# DA14581 register map
Vendor: Dialog; Series: DA1458x; File version: 1.2
Ultra-Low power Bleutooth 4.2 SoC with Optimized Boot Time from Dialog Semiconductor
CPU: CM0 r1p0, little endian, MPU, FPU, 3 interrupt priority bits
Registers are 16-bit, read-write, reset 0x0 unless marked. A register's access mark holds for its fields unless they carry their own. Offsets are from the block's base; lines under a group give offsets from that group; [hi:lo] are bit positions; {n}, {i} and the like mark numbered series; 'fields as' and 'values as' point back to an identical list; <NAME> marks a mode.

## Memory map
0x40000000 ble580_gr01 size 0x208 — ble580_gr01 registers
0x40008000 otpc580_gr01 size 0x20 — otpc580_gr01 registers
0x50000000 crg580_nl01 size 0x2C — crg580_nl01 registers
0x50000080 crg580_dcdc_nl01 size 0x6 — crg580_dcdc_nl01 registers
0x50000100 wkup580_nl01 size 0x1A — wkup580_nl01 registers
0x50000200 quadec580_gr01 size 0xC — quadec580_gr01 registers
0x50001000 UART1 size 0xFE — UART1 registers
0x50001100 UART2 size 0xFE — UART2 registers
0x50001200 spi443_nl00 size 0xA — spi443_nl00 registers
0x50001300 i2c580_nl00 size 0xA2 — i2c580_nl00 registers
0x50001400 kbrd580_nl01 size 0x18 — kbrd580_nl01 registers
0x50001500 adc580_bif_nl01 size 0x10 — adc580_bif_nl01 registers
0x50001600 anamisc580_nl01 size 0x8 — anamisc580_nl01 registers
0x50003000 gpio580_ports_nl01 size 0x96 — gpio580_ports_nl01 registers
0x50003100 riscutil580_wdog_nl00 size 0x4 — riscutil580_wdog_nl00 registers
0x50003200 CHIP_VERSION size 0x5 — CHIP_VERSION registers
0x50003300 riscutil580_gpreg_nl01 size 0xA — riscutil580_gpreg_nl01 registers
0x50003400 tmr580_nl01 size 0x12 — tmr580_nl01 registers
0xE000E010 SysTick size 0x11 — Cortex M0 SysTick registers
0xE000E100 NVIC size 0x321 — Cortex M0 NVIC registers
0xE000ED00 SCB size 0x29 — Cortex M0 SCB registers

## Interrupts
0 BLE_WAKEUP_LP (wkup580_nl01) — Wake-up from Low Power (Extended Sleep) interrupt from BLE
1 BLE_GEN (wkup580_nl01) — BLE Interrupt from various BLE sources.
2 UART (wkup580_nl01) — UART interrupt
3 UART2 (wkup580_nl01) — UART2 interrupt
4 I2C (wkup580_nl01) — I2C interrupt
5 SPI (wkup580_nl01) — SPI interrupt
6 ADC (wkup580_nl01) — Analog-Digital Converter interrupt.
7 KEYBRD (wkup580_nl01) — Keyboard interrupt.
8 BLE_RF_DIAG (wkup580_nl01) — Baseband or Radio Diagnostics Interrupt
9 RF_CAL (wkup580_nl01) — RF Calibration Interrupt
10 GPIO0 (wkup580_nl01) — GPIO0 interrupt through debounce
11 GPIO1 (wkup580_nl01) — GPIO1 interrupt through debounce
12 GPIO2 (wkup580_nl01) — GPIO2 interrupt through debounce
13 GPIO3 (wkup580_nl01) — GPIO3 interrupt through debounce
14 GPIO4 (wkup580_nl01) — GPIO4 interrupt through debounce
15 SWTIM (wkup580_nl01) — Software Timer interrupt
16 WKUP_QUADEC (wkup580_nl01) — Combines the Wake up Capture Timer interrupt, the GPIO interrupt and the QuadDecoder interrupt
17 PCM (wkup580_nl01) — PCM interrupt
18 SRC_IN (wkup580_nl01) — Sample rate converter input interrupt
19 SRC_OUT (wkup580_nl01) — Sample rate converter output interrupt
20 DMA (wkup580_nl01) — DMA interrupt

## SCB — Cortex M0 SCB registers
Base 0xE000ED00
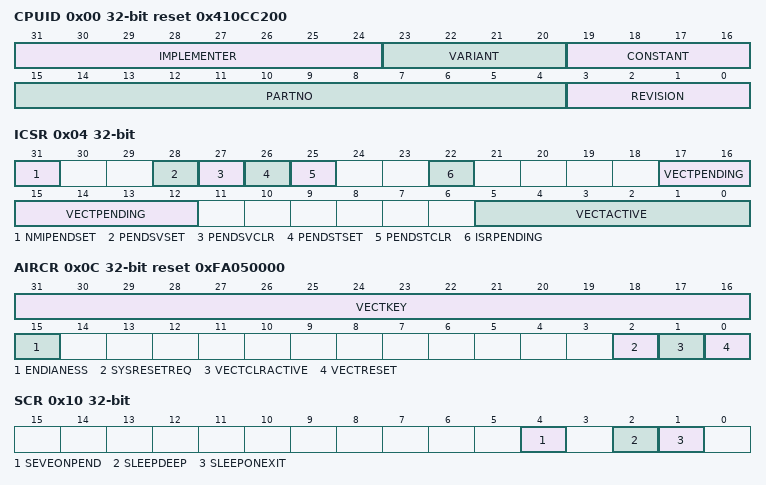
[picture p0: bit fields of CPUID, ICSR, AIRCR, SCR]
0x00 CPUID 32-bit reset 0x410CC200 — CPUID base register
  [31:24] IMPLEMENTER ro — IMPLEMENTER[7:0] bits (Implementer code)
  [23:20] VARIANT ro — VARIANT[3:0] bits (Variant number)
  [19:16] CONSTANT ro — CONSTANT[3:0] bits (Reads as 0xF)
  [15:4] PARTNO ro — PARTNO[11:0] bits (Part number of the processor core)
  [3:0] REVISION ro — REVISION[3:0] bits (Revision number)
0x04 ICSR 32-bit — Interrupt control and state register
  [31] NMIPENDSET — NMI set-pending bit
  [28] PENDSVSET — PendSV set-pending bit
  [27] PENDSVCLR — PendSV clear-pending bit
  [26] PENDSTSET — SysTick exception set-pending bit
  [25] PENDSTCLR — SysTick exception clear-pending bit
  [22] ISRPENDING — Interrupt pending flag, excluding NMI and Faults
  [17:12] VECTPENDING — VECTPENDING[5:0] bits (Pending vector)
  [5:0] VECTACTIVE — VECTACTIVE[5:0] bits (Active vector)
0x0C AIRCR 32-bit ro reset 0xFA050000 — Application interrupt and reset control register
  [31:16] VECTKEY — VECTKEY[15:0] bits (Register key)
  [15] ENDIANESS — Data endianness bit
  [2] SYSRESETREQ — System reset request
  [1] VECTCLRACTIVE — Reserved for Debug use
  [0] VECTRESET — Reserved for Debug use
0x10 SCR 32-bit — System control register
  [4] SEVEONPEND — Send event on pending bit
  [2] SLEEPDEEP — Controls whether the processor uses sleep or deep sleep
  [1] SLEEPONEXIT — Configures sleep-on-exit when returning from Handler mode to Thread mode
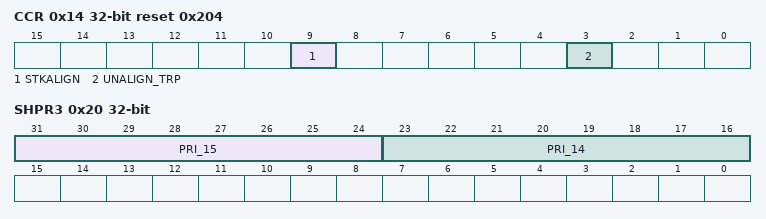
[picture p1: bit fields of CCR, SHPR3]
0x14 CCR 32-bit reset 0x204 — Configuration and control register
  [9] STKALIGN — Configures stack alignment on exception entry
  [3] UNALIGN_TRP — Enables unaligned access traps
0x1C SHPR2 32-bit — System handler priority register 2
  [31:24] PRI_11 — PRI_11[7:0] bits (Priority of system handler 11, SVCall)
0x20 SHPR3 32-bit — System handler priority register 3
  [31:24] PRI_15 — PRI_15[7:0] bits (Priority of system handler 15, SysTick exception)
  [23:16] PRI_14 — PRI_14[7:0] bits (Priority of system handler 14, PendSV)

## Licence text in the file
Copyright (C) 2018 Dialog Semiconductor. This computer program includes Confidential, Proprietary Information of Dialog Semiconductor. All Rights Reserved. . Dialog GmbH (DLG) is supplying this software for use with Cortex-M processor based microcontroller, but can be equally used for other suitable processor architectures. This file can be freely distributed. Modifications to this file shall be clearly marked. . THIS SOFTWARE IS PROVIDED AS IS . NO WARRANTIES, WHETHER EXPRESS, IMPLIED. OR STATUTORY, INCLUDING, BUT NOT LIMITED TO, IMPLIED WARRANTIES OF. MERCHANTABILITY AND FITNESS FOR A PARTICULAR PURPOSE APPLY TO THIS SOFTWARE. ARM SHALL NOT, IN ANY CIRCUMSTANCES, BE LIABLE FOR SPECIAL, INCIDENTAL, OR. CONSEQUENTIAL DAMAGES, FOR ANY REASON WHATSOEVER.
